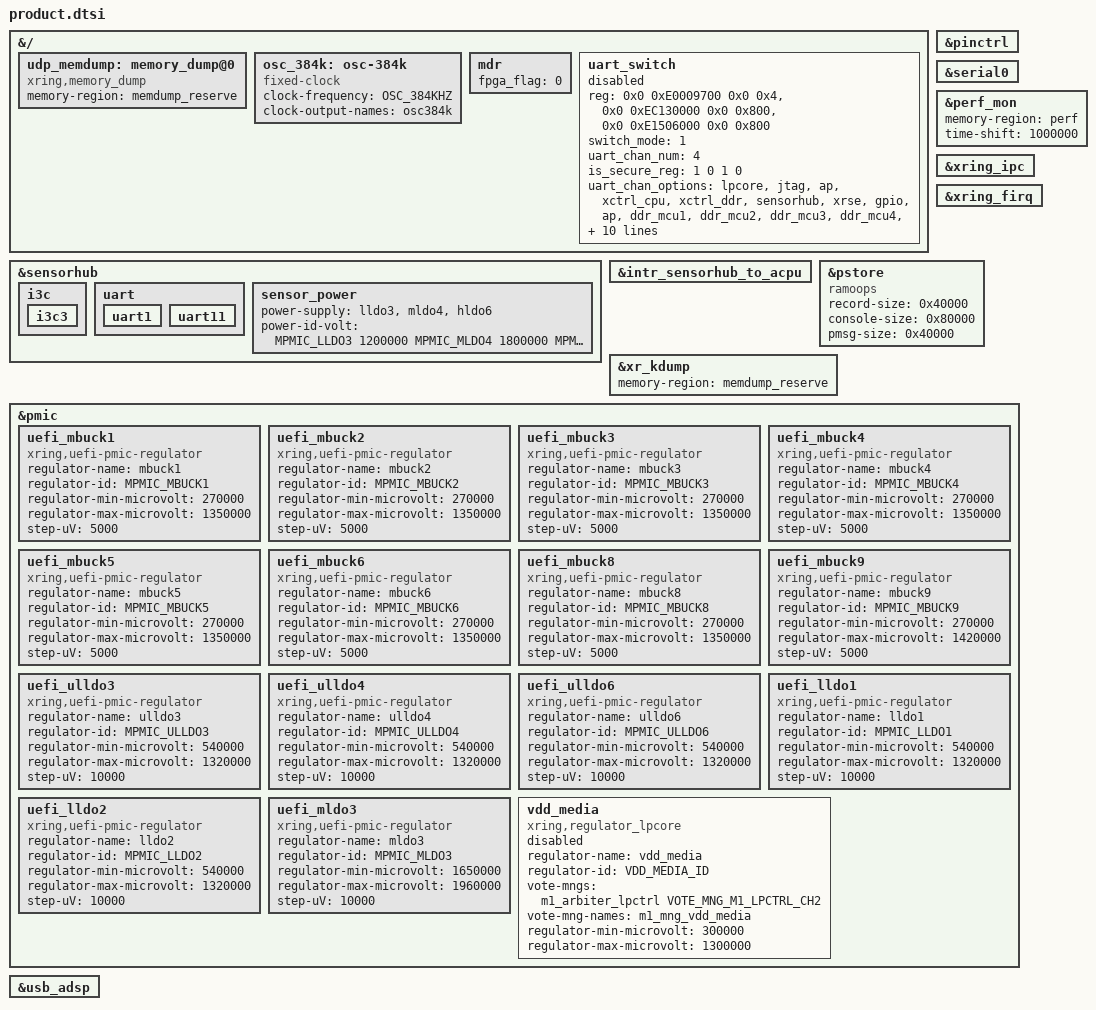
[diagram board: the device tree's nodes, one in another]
// SPDX-License-Identifier: (GPL-2.0+ OR MIT)
/*
 * Copyright 2022 XiaoMi
 */

#include <dt-bindings/xring/platform-specific/pmic/pmic_regulator_def.h>
#include <dt-bindings/xring/platform-specific/ip_regulator_define.h>
#include <dt-bindings/xring/vote_mng_define.h>

#define OSC_384KHZ 38400000

&{/} {
    #size-cells = <2>;
    #address-cells = <2>;

    udp_memdump: memory_dump@0 {
        compatible = "xring,memory_dump";
        memory-region = <&memdump_reserve>;
        status = "okay";
    };

    osc_384k: osc-384k {
        compatible = "fixed-clock";
        #clock-cells = <0x00>;
        clock-frequency = <OSC_384KHZ>;
        clock-output-names = "osc384k";
    };

    mdr {
        fpga_flag = <0>;
    };

    uart_switch {
        status = "disabled";
        reg = <0x0 0xE0009700 0x0 0x4>, /* SYS_CTRL_POR_REG_SC_REG_USEC0 */
              <0x0 0xEC130000 0x0 0x800>, /* ACPU_PERI_IOCTRL */
              <0x0 0xE1506000 0x0 0x800>; /* ACPU_LPIS_IOC */
        switch_mode = <1>; /* Switch by IOMUX */
        uart_chan_num = <4>;
        /* Indicates security attribute of each channel's config register */
        is_secure_reg = <1 0 1 0>;
        /* switching options of each channel */
        uart_chan_options = "lpcore", "jtag", "ap", "xctrl_cpu", "xctrl_ddr", "sensorhub", "xrse",
                            "gpio", "ap", "ddr_mcu1", "ddr_mcu2", "ddr_mcu3", "ddr_mcu4",
                            "gpio", "xrse", "spi2", "xctrl_ddr", "npu",
                            "gpio", "i2c15", "xctrl_cpu", "npu", "sensorhub", "adsp", "isp";
        /* uart channel that each option belongs to */
        uart_chans = <1 1 1 1 1 1 1
                      2 2 2 2 2 2
                      3 3 3 3 3
                      4 4 4 4 4 4 4>;
        /* SCTRL value of each option */
        sctrl_val = <0 0 0 0 0 0 0
                     0 0 0 0 0 0
                     0 0 0 0 0x1000
                     0 0 0 0 0 0 0>;
        /* SCTRL mask of each option */
        sctrl_mask = <0x10000 0x0 0x20000 0x40000 0x80000 0x400000 0x200000
                      0x0 0x20000 0x2000000 0x2000000 0x2000000 0x2000000
                      0x0 0x200000 0x0 0x10080000 0x10080000
                      0x0 0x0 0x40000 0x100000 0x400000 0x800000 0x1000000>;
        /* IOMUX value of each option */
        config_val = <0 1 2 3 4 5 6
                      0 1 2 3 4 5
                      0 1 2 3 3
                      0 1 2 3 4 5 6>;
    };
};

&pinctrl {
    status = "okay";
};

&serial0 {
    status = "okay";
};

&perf_mon {
    status = "okay";
    memory-region = <&perf>;
    time-shift = <1000000>; /* FPGA:10M, ASIC:200M */
};

&xring_ipc {
    status = "okay";
};

&sensorhub {
    status = "okay";
    i3c {
        status = "okay";
        i3c3 {
            status = "okay";
        };
    };
    uart {
        status = "okay";
        uart1 {
            status = "okay";
        };
        uart11 {
            status = "okay";
        };
    };
    sensor_power {
        status = "okay";
        power-supply = <&lldo3 &mldo4 &hldo6>;
        power-id-volt = <MPMIC_LLDO3 1200000 MPMIC_MLDO4 1800000 MPMIC_HLDO6 3300000>;
    };
};

&xring_firq {
    status = "okay";
};

&intr_sensorhub_to_acpu {
    status = "okay";
};

&pstore {
	compatible = "ramoops";
	record-size = <0x40000>;
	console-size = <0x80000>;
	pmsg-size = <0x40000>;
};

&xr_kdump {
	status = "okay";
	memory-region = <&memdump_reserve>;
};

&pmic {
    uefi_mbuck1: uefi_mbuck1 {
        compatible = "xring,uefi-pmic-regulator";
        regulator-name = "mbuck1";
        regulator-id = <MPMIC_MBUCK1>;
        regulator-min-microvolt = <270000>;
        regulator-max-microvolt = <1350000>;
        step-uV = <5000>;
    };

    uefi_mbuck2: uefi_mbuck2 {
        compatible = "xring,uefi-pmic-regulator";
        regulator-name = "mbuck2";
        regulator-id = <MPMIC_MBUCK2>;
        regulator-min-microvolt = <270000>;
        regulator-max-microvolt = <1350000>;
        step-uV = <5000>;
    };

    uefi_mbuck3: uefi_mbuck3 {
        compatible = "xring,uefi-pmic-regulator";
        regulator-name = "mbuck3";
        regulator-id = <MPMIC_MBUCK3>;
        regulator-min-microvolt = <270000>;
        regulator-max-microvolt = <1350000>;
        step-uV = <5000>;
    };

    uefi_mbuck4: uefi_mbuck4 {
        compatible = "xring,uefi-pmic-regulator";
        regulator-name = "mbuck4";
        regulator-id = <MPMIC_MBUCK4>;
        regulator-min-microvolt = <270000>;
        regulator-max-microvolt = <1350000>;
        step-uV = <5000>;
    };

    uefi_mbuck5: uefi_mbuck5 {
        compatible = "xring,uefi-pmic-regulator";
        regulator-name = "mbuck5";
        regulator-id = <MPMIC_MBUCK5>;
        regulator-min-microvolt = <270000>;
        regulator-max-microvolt = <1350000>;
        step-uV = <5000>;
    };

    uefi_mbuck6: uefi_mbuck6 {
        compatible = "xring,uefi-pmic-regulator";
        regulator-name = "mbuck6";
        regulator-id = <MPMIC_MBUCK6>;
        regulator-min-microvolt = <270000>;
        regulator-max-microvolt = <1350000>;
        step-uV = <5000>;
    };

    uefi_mbuck8: uefi_mbuck8 {
        compatible = "xring,uefi-pmic-regulator";
        regulator-name = "mbuck8";
        regulator-id = <MPMIC_MBUCK8>;
        regulator-min-microvolt = <270000>;
        regulator-max-microvolt = <1350000>;
        step-uV = <5000>;
    };

    uefi_mbuck9: uefi_mbuck9 {
        compatible = "xring,uefi-pmic-regulator";
        regulator-name = "mbuck9";
        regulator-id = <MPMIC_MBUCK9>;
        regulator-min-microvolt = <270000>;
        regulator-max-microvolt = <1420000>;
        step-uV = <5000>;
    };

    uefi_ulldo3: uefi_ulldo3 {
        compatible = "xring,uefi-pmic-regulator";
        regulator-name = "ulldo3";
        regulator-id = <MPMIC_ULLDO3>;
        regulator-min-microvolt = <540000>;
        regulator-max-microvolt = <1320000>;
        step-uV = <10000>;
    };

    uefi_ulldo4: uefi_ulldo4 {
        compatible = "xring,uefi-pmic-regulator";
        regulator-name = "ulldo4";
        regulator-id = <MPMIC_ULLDO4>;
        regulator-min-microvolt = <540000>;
        regulator-max-microvolt = <1320000>;
        step-uV = <10000>;
    };

    uefi_ulldo6: uefi_ulldo6 {
        compatible = "xring,uefi-pmic-regulator";
        regulator-name = "ulldo6";
        regulator-id = <MPMIC_ULLDO6>;
        regulator-min-microvolt = <540000>;
        regulator-max-microvolt = <1320000>;
        step-uV = <10000>;
    };

    uefi_lldo1: uefi_lldo1 {
        compatible = "xring,uefi-pmic-regulator";
        regulator-name = "lldo1";
        regulator-id = <MPMIC_LLDO1>;
        regulator-min-microvolt = <540000>;
        regulator-max-microvolt = <1320000>;
        step-uV = <10000>;
    };

    uefi_lldo2: uefi_lldo2 {
        compatible = "xring,uefi-pmic-regulator";
        regulator-name = "lldo2";
        regulator-id = <MPMIC_LLDO2>;
        regulator-min-microvolt = <540000>;
        regulator-max-microvolt = <1320000>;
        step-uV = <10000>;
    };

    uefi_mldo3: uefi_mldo3 {
        compatible = "xring,uefi-pmic-regulator";
        regulator-name = "mldo3";
        regulator-id = <MPMIC_MLDO3>;
        regulator-min-microvolt = <1650000>;
        regulator-max-microvolt = <1960000>;
        step-uV = <10000>;
    };

    vdd_media: vdd_media{
        compatible = "xring,regulator_lpcore";
        regulator-name = "vdd_media";
        regulator-id = <VDD_MEDIA_ID>;
        vote-mngs = <&m1_arbiter_lpctrl VOTE_MNG_M1_LPCTRL_CH2>;
        vote-mng-names = "m1_mng_vdd_media";
        regulator-min-microvolt = <300000>;
        regulator-max-microvolt = <1300000>;
        status = "disabled"; /* only available in UEFI */
    };
};

&usb_adsp {
    status = "okay";
};
